AUTOSAR XML (schema 00050)
package /FCADT/ComponentTypes
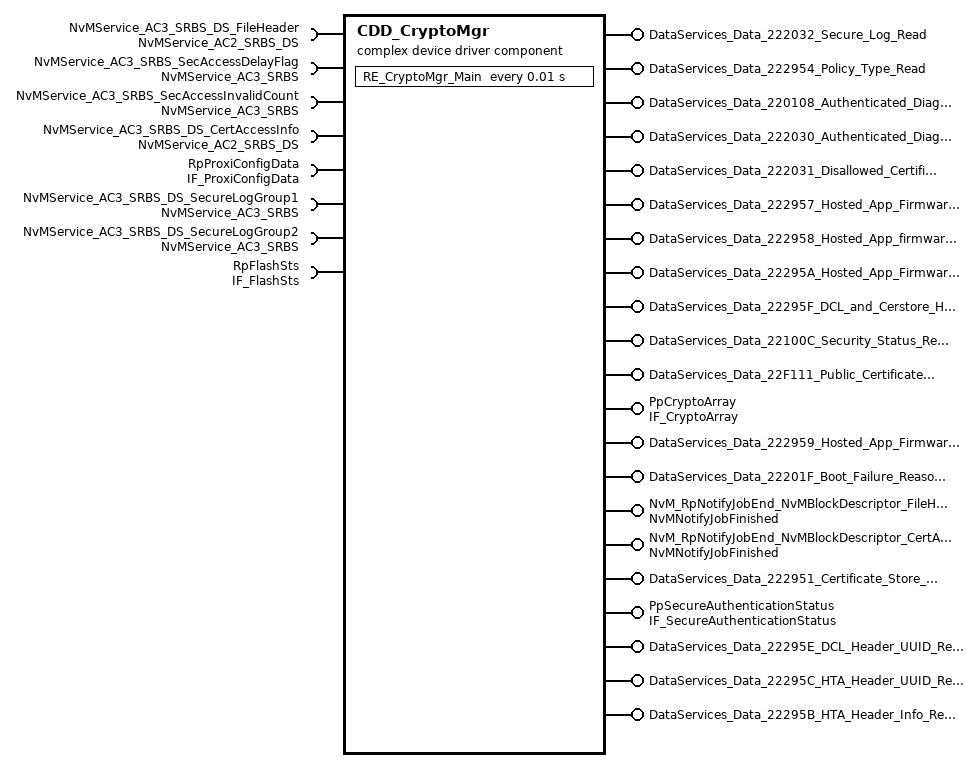
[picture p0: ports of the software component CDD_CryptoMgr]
  complex device driver sw component type CDD_CryptoMgr
    15 x provide port:
      DataServices_Data_222032_Secure_Log_Read: server-com-spec{operation=ReadData, queue-length=1}, provided-interface=DataServices_Data_222032_Secure_Log_Read
      DataServices_Data_222954_Policy_Type_Read: server-com-spec{operation=ReadData, queue-length=1}, provided-interface=DataServices_Data_222954_Policy_Type_Read
      DataServices_Data_220108_Authenticated_Diagnostics_Active_Role_Read: server-com-spec{operation=ReadData, queue-length=1}, provided-interface=DataServices_Data_220108_Authenticated_Diagnostics_Active_Role_Read
      DataServices_Data_222030_Authenticated_Diagnostic_Previous_Access_Read: server-com-spec{operation=ReadData, queue-length=1}, provided-interface=DataServices_Data_222030_Authenticated_Diagnostic_Previous_Access_Read
      DataServices_Data_222031_Disallowed_Certificate_List_Read: server-com-spec{operation=ReadData, queue-length=1}, provided-interface=DataServices_Data_222031_Disallowed_Certificate_List_Read
      DataServices_Data_222957_Hosted_App_Firmware_Header_Info_Read: server-com-spec{operation=ReadData, queue-length=1}, provided-interface=DataServices_Data_222957_Hosted_App_Firmware_Header_Info_Read
      DataServices_Data_222958_Hosted_App_firmware_Header_UUID_Read: server-com-spec{operation=ReadData, queue-length=1}, provided-interface=DataServices_Data_222958_Hosted_App_firmware_Header_UUID_Read
      DataServices_Data_22295A_Hosted_App_Firmware_Cal_Config_Data_Header_UUID_Read: server-com-spec{operation=ReadData, queue-length=1}, provided-interface=DataServices_Data_22295A_Hosted_App_Firmware_Cal_Config_Data_Header_UUID_Read
      DataServices_Data_22295F_DCL_and_Cerstore_Header_Info_Read: server-com-spec{operation=ReadData, queue-length=1}, provided-interface=DataServices_Data_22295F_DCL_and_Cerstore_Header_Info_Read
      DataServices_Data_22100C_Security_Status_Read: server-com-spec{operation=ReadData, queue-length=1}, provided-interface=DataServices_Data_22100C_Security_Status_Read
      DataServices_Data_22F111_Public_Certificates_Regional_Support_Read: server-com-spec{operation=ReadData, queue-length=1}, provided-interface=DataServices_Data_22F111_Public_Certificates_Regional_Support_Read
      PpCryptoArray: server-com-spec{operation=CryptoArray, queue-length=1}, provided-interface=IF_CryptoArray
      DataServices_Data_222959_Hosted_App_Firmware_Cal_Config_Data_Header_Info_Read: server-com-spec{operation=ReadData, queue-length=1}, provided-interface=DataServices_Data_222959_Hosted_App_Firmware_Cal_Config_Data_Header_Info_Read
      DataServices_Data_22201F_Boot_Failure_Reason_Read: server-com-spec{operation=ReadData, queue-length=1}, provided-interface=DataServices_Data_22201F_Boot_Failure_Reason_Read
      NvM_RpNotifyJobEnd_NvMBlockDescriptor_FileHeader: server-com-spec{operation=JobFinished, queue-length=1}, provided-interface=NvMNotifyJobFinished
    4 x require port:
      NvMService_AC3_SRBS_DS_FileHeader: required-com-specs=[WriteBlock, SetRamBlockStatus, SetDataIndex, ReadBlock, GetErrorStatus, GetDataIndex], required-interface=NvMService_AC2_SRBS_DS
      NvMService_AC3_SRBS_SecAccessDelayFlag: required-com-specs=[WriteBlock, SetRamBlockStatus, ReadBlock, InvalidateNvBlock, GetErrorStatus, EraseBlock], required-interface=NvMService_AC3_SRBS
      NvMService_AC3_SRBS_SecAccessInvalidCount: required-com-specs=[WriteBlock, SetRamBlockStatus, ReadBlock, InvalidateNvBlock, GetErrorStatus, EraseBlock], required-interface=NvMService_AC3_SRBS
      NvMService_AC3_SRBS_DS_CertAccessInfo: required-com-specs=[WriteBlock, SetRamBlockStatus, SetDataIndex, ReadBlock, GetErrorStatus, GetDataIndex], required-interface=NvMService_AC2_SRBS_DS
    provide port NvM_RpNotifyJobEnd_NvMBlockDescriptor_CertAccessInfo: server-com-spec{operation=JobFinished, queue-length=1}, provided-interface=NvMNotifyJobFinished
    require port RpProxiConfigData: nonqueued-receiver-com-spec{data-element=ProxiData, filter=data-filter-type=ALWAYS}, required-interface=IF_ProxiConfigData
    provide port DataServices_Data_222951_Certificate_Store_UUID_Read: server-com-spec{operation=ReadData, queue-length=1}, provided-interface=DataServices_Data_222951_Certificate_Store_UUID_Read
    provide port PpSecureAuthenticationStatus: server-com-spec{operation=Get_ADAStatus, queue-length=1}, provided-interface=IF_SecureAuthenticationStatus
    require port NvMService_AC3_SRBS_DS_SecureLogGroup1: required-com-specs=[WriteBlock, SetRamBlockStatus, ReadBlock, InvalidateNvBlock, GetErrorStatus, EraseBlock], required-interface=NvMService_AC3_SRBS
    require port NvMService_AC3_SRBS_DS_SecureLogGroup2: required-com-specs=[WriteBlock, SetRamBlockStatus, ReadBlock, InvalidateNvBlock, GetErrorStatus, EraseBlock], required-interface=NvMService_AC3_SRBS
    provide port DataServices_Data_22295E_DCL_Header_UUID_Read: server-com-spec{operation=ReadData, queue-length=1}, provided-interface=DataServices_Data_22295E_DCL_Header_UUID_Read
    provide port DataServices_Data_22295C_HTA_Header_UUID_Read: server-com-spec{operation=ReadData, queue-length=1}, provided-interface=DataServices_Data_22295C_HTA_Header_UUID_Read
    provide port DataServices_Data_22295B_HTA_Header_Info_Read: server-com-spec{operation=ReadData, queue-length=1}, provided-interface=DataServices_Data_22295B_HTA_Header_Info_Read
    require port RpFlashSts: nonqueued-receiver-com-spec{data-element=v_FlashSts_u16, filter=data-filter-type=ALWAYS, init-value=0}, required-interface=IF_FlashSts
    behavior CDD_CryptoMgr_InternalBehavior
      ar-typed-per-instance-memorys:
        7 x data, all with sw-calibration-access=READ-ONLY:
          Rte_CDD_CryptoMgr_Rte_SWC_CDD_CryptoMngr_SecAccessDelayFlag_MirrorBlock: type=uint8, init-value=0
          Rte_CDD_CryptoMgr_Rte_SWC_CDD_CryptoMngr_SecAccessInvalidCount_MirrorBlock: type=uint8, init-value=0
          Rte_SWC_CDD_CryptoMngr_SecureLogGroup1_MirrorBlock: type=SecureLogRecord_t
          Rte_SWC_CDD_CryptoMngr_SecureLogGroup2_MirrorBlock: type=SecureLogRecord_t
          NvMBlockDescriptor_SecondCounter_MirrorBlock: type=uint32, init-value=0
          NvMBlockDescriptor_SystemTimestamp_MirrorBlock: type=Array_15Bytes, init-value=15 x 0
          NvMBlockDescriptor_CertificateExpired_MirrorBlock: type=boolean, init-value=0
      init event CDD_CryptoMgr_InitEvent: start-on-event=RE_CryptoMgr_Init
      timing event TMT_RE_CryptoMgr_Main: start-on-event=RE_CryptoMgr_Main, period=0.01
      21 x operation invoked event:
        OIT_DataServices_Data_222032_Secure_Log_Read_ReadData_DataServices_Data_222032_Secure_Log_Read_ReadData: start-on-event=DataServices_Data_222032_Secure_Log_Read_ReadData, operation=DataServices_Data_222032_Secure_Log_Read.ReadData
        OIT_DataServices_Data_22295A_Hosted_App_Firmware_Cal_Config_Data_Header_UUID_Read_ReadData_DataServices_Data_22295A_Host0363ECC3: start-on-event=DataServices_Data_22295A_Hosted_App_Firmware_Cal_Config_Data_Header_UUID_Read_ReadData, operation=DataServices_Data_22295A_Hosted_App_Firmware_Cal_Config_Data_Header_UUID_Read.ReadData
        OIT_DataServices_Data_222031_Disallowed_Certificate_List_Read_ReadData_DataServices_Data_222031_Disallowed_Certificate_LC9ECC53E: start-on-event=DataServices_Data_222031_Disallowed_Certificate_List_Read_ReadData, operation=DataServices_Data_222031_Disallowed_Certificate_List_Read.ReadData
        OIT_DataServices_Data_222957_Hosted_App_Firmware_Header_Info_Read_ReadData_DataServices_Data_222957_Hosted_App_Firmware_59835101: start-on-event=DataServices_Data_222957_Hosted_App_Firmware_Header_Info_Read_ReadData, operation=DataServices_Data_222957_Hosted_App_Firmware_Header_Info_Read.ReadData
        OIT_DataServices_Data_220108_Authenticated_Diagnostics_Active_Role_Read_ReadData_DataServices_Data_220108_Authenticated_1848ABFC: start-on-event=DataServices_Data_220108_Authenticated_Diagnostics_Active_Role_Read_ReadData, operation=DataServices_Data_220108_Authenticated_Diagnostics_Active_Role_Read.ReadData
        OIT_DataServices_Data_22295F_DCL_and_Cerstore_Header_Info_Read_ReadData_DataServices_Data_22295F_DCL_and_Cerstore_Header5E694DD0: start-on-event=DataServices_Data_22295F_DCL_and_Cerstore_Header_Info_Read_ReadData, operation=DataServices_Data_22295F_DCL_and_Cerstore_Header_Info_Read.ReadData
        OIT_DataServices_Data_22F111_Public_Certificates_Regional_Support_Read_ReadData_DataServices_Data_22F111_Public_Certific9DA6A63E: start-on-event=DataServices_Data_22F111_Public_Certificates_Regional_Support_Read_ReadData, operation=DataServices_Data_22F111_Public_Certificates_Regional_Support_Read.ReadData
        OIT_DataServices_Data_22100C_Security_Status_Read_ReadData_DataServices_Data_22100C_Security_Status_Read_ReadData: start-on-event=DataServices_Data_22100C_Security_Status_Read_ReadData, operation=DataServices_Data_22100C_Security_Status_Read.ReadData
        OIT_DataServices_Data_222958_Hosted_App_firmware_Header_UUID_Read_ReadData_DataServices_Data_222958_Hosted_App_firmware_60C8C4CE: start-on-event=DataServices_Data_222958_Hosted_App_firmware_Header_UUID_Read_ReadData, operation=DataServices_Data_222958_Hosted_App_firmware_Header_UUID_Read.ReadData
        OIT_DataServices_Data_222954_Policy_Type_Read_ReadData_DataServices_Data_222954_Policy_Type_Read_ReadData: start-on-event=DataServices_Data_222954_Policy_Type_Read_ReadData, operation=DataServices_Data_222954_Policy_Type_Read.ReadData
        OIT_DataServices_Data_222030_Authenticated_Diagnostic_Previous_Access_Read_ReadData_DataServices_Data_222030_Authenticat5BBDD058: start-on-event=DataServices_Data_222030_Authenticated_Diagnostic_Previous_Access_Read_ReadData, operation=DataServices_Data_222030_Authenticated_Diagnostic_Previous_Access_Read.ReadData
        OIT_PpCryptoArray_CryptoArray_PpCryptoArray_CryptoArray: start-on-event=RE_CryptoArray_CryptoArray, operation=PpCryptoArray.CryptoArray
        OIT_DataServices_Data_22201F_Boot_Failure_Reason_Read_ReadData_DataServices_Data_22201F_Boot_Failure_Reason_Read_ReadData: start-on-event=DataServices_Data_22201F_Boot_Failure_Reason_Read_ReadData, operation=DataServices_Data_22201F_Boot_Failure_Reason_Read.ReadData
        OIT_DataServices_Data_222959_Hosted_App_Firmware_Cal_Config_Data_Header_Info_Read_ReadData_DataServices_Data_222959_Host82557262: start-on-event=DataServices_Data_222959_Hosted_App_Firmware_Cal_Config_Data_Header_Info_Read_ReadData, operation=DataServices_Data_222959_Hosted_App_Firmware_Cal_Config_Data_Header_Info_Read.ReadData
        OIT_RE_NvM_RpNotifyJobEnd_NvMBlockDescriptor_FileHeader_JobFinished_NvM_RpNotifyJobEnd_NvMBlockDescriptor_FileHeader_JobFinished: start-on-event=RE_NvM_RpNotifyJobEnd_NvMBlockDescriptor_FileHeader_JobFinished, operation=NvM_RpNotifyJobEnd_NvMBlockDescriptor_FileHeader.JobFinished
        OIT_NvM_RpNotifyJobEnd_NvMBlockDescriptor_CertAccessInfo_JobFinished_NvM_RpNotifyJobEnd_NvMBlockDescriptor_CertAccessInf1353BA01: start-on-event=RE_NvM_RpNotifyJobEnd_NvMBlockDescriptor_CertAccessInfo_JobFinished, operation=NvM_RpNotifyJobEnd_NvMBlockDescriptor_CertAccessInfo.JobFinished
        OIT_DataServices_Data_222951_Certificate_Store_UUID_Read_ReadData_DataServices_Data_222951_Certificate_Store_UUID_Read_ReadData: start-on-event=DataServices_Data_222951_Certificate_Store_UUID_Read_ReadData, operation=DataServices_Data_222951_Certificate_Store_UUID_Read.ReadData
        OIT_PpSecureAuthenticationStatus_Get_SecureAuthenticationStatus_PpSecureAuthenticationStatus_Get_SecureAuthenticationStatus: start-on-event=RE_Get_SecureAuthenticationStatus, operation=PpSecureAuthenticationStatus.Get_ADAStatus
        OIT_Runnable_DataServices_Data_22295E_DCL_Header_UUID_Read_ReadData: start-on-event=DataServices_Data_22295E_DCL_Header_UUID_Read, operation=DataServices_Data_22295E_DCL_Header_UUID_Read.ReadData
        OIT_DataServices_Data_22295B_HTA_Header_Info_Read_DataServices_Data_22295B_HTA_Header_Info_Read_ReadData: start-on-event=DataServices_Data_22295B_HTA_Header_Info_Read, operation=DataServices_Data_22295B_HTA_Header_Info_Read.ReadData
        OIT_Runnable_DataServices_Data_22295C_HTA_Header_UUID_Read_ReadData: start-on-event=DataServices_Data_22295C_HTA_Header_UUID_Read, operation=DataServices_Data_22295C_HTA_Header_UUID_Read.ReadData
      per-instance-parameters:
        7 x parameter data prototype:
          Rte_CDD_CryptoMgr_Rte_SWC_CDD_CryptoMngr_SecAccessDelayFlag_DefaultValue: sw-calibration-access=READ-WRITE, type=uint8, init-value=0
          Rte_CDD_CryptoMgr_Rte_SWC_CDD_CryptoMngr_SecAccessInvalidCount_DefaultValue: sw-calibration-access=READ-WRITE, type=uint8, init-value=0
          Rte_SWC_CDD_CryptoMngr_SecureLogGroup1_DefaultValue: sw-calibration-access=READ-WRITE, type=SecureLogRecord_t
          Rte_SWC_CDD_CryptoMngr_SecureLogGroup2_DefaultValue: sw-calibration-access=READ-WRITE, type=SecureLogRecord_t
          NvMBlockDescriptor_SecondCounter_DefaultValue: sw-calibration-access=READ-ONLY, type=uint32, init-value=0
          NvMBlockDescriptor_SystemTimestamp_DefaultValue: sw-calibration-access=READ-WRITE, type=Array_15Bytes, init-value=15 x 0
          NvMBlockDescriptor_CertificateExpired_DefaultValue: sw-calibration-access=READ-WRITE, type=boolean, init-value=0
      23 x runnable:
        RE_CryptoMgr_Init
          4 x sync call:
            SC_NvMService_AC3_SRBS_DS_FileHeader_ReadBlock: operation=NvMService_AC3_SRBS_DS_FileHeader.ReadBlock
            SC_NvMService_AC3_SRBS_DS_FileHeader_SetDataIndex: operation=NvMService_AC3_SRBS_DS_FileHeader.SetDataIndex
            SC_NvMService_AC3_SRBS_DS_CertAccessInfo_ReadBlock: operation=NvMService_AC3_SRBS_DS_CertAccessInfo.ReadBlock
            SC_NvMService_AC3_SRBS_DS_CertAccessInfo_SetDataIndex: operation=NvMService_AC3_SRBS_DS_CertAccessInfo.SetDataIndex
        RE_CryptoMgr_Main
          data-receive-point-by-arguments:
            access REC_RpFlashSts_v_FlashSts_u16: accessed-variable=RpFlashSts.v_FlashSts_u16
            access REC_RpProxiConfigData_ProxiData: accessed-variable=RpProxiConfigData.ProxiData
          11 x sync call:
            SC_NvMService_AC3_SRBS_SecAccessDelayFlag_GetErrorStatus: operation=NvMService_AC3_SRBS_SecAccessDelayFlag.GetErrorStatus
            SC_NvMService_AC3_SRBS_SecAccessDelayFlag_WriteBlock: operation=NvMService_AC3_SRBS_SecAccessDelayFlag.WriteBlock
            SC_NvMService_AC3_SRBS_SecAccessInvalidCount_GetErrorStatus: operation=NvMService_AC3_SRBS_SecAccessInvalidCount.GetErrorStatus
            SC_NvMService_AC3_SRBS_SecAccessInvalidCount_WriteBlock: operation=NvMService_AC3_SRBS_SecAccessInvalidCount.WriteBlock
            SC_NvMService_AC3_SRBS_DS_CertAccessInfo_WriteBlock: operation=NvMService_AC3_SRBS_DS_CertAccessInfo.WriteBlock
            SC_NvMService_AC3_SRBS_DS_SecureLogGroup1_SetRamBlockStatus: operation=NvMService_AC3_SRBS_DS_SecureLogGroup1.SetRamBlockStatus
            SC_NvMService_AC3_SRBS_DS_SecureLogGroup2_SetRamBlockStatus: operation=NvMService_AC3_SRBS_DS_SecureLogGroup2.SetRamBlockStatus
            SC_NvMService_AC3_SRBS_DS_SecureLogGroup1_GetErrorStatus: operation=NvMService_AC3_SRBS_DS_SecureLogGroup1.GetErrorStatus
            SC_NvMService_AC3_SRBS_DS_SecureLogGroup1_ReadBlock: operation=NvMService_AC3_SRBS_DS_SecureLogGroup1.ReadBlock
            SC_NvMService_AC3_SRBS_DS_SecureLogGroup2_GetErrorStatus: operation=NvMService_AC3_SRBS_DS_SecureLogGroup2.GetErrorStatus
            SC_NvMService_AC3_SRBS_DS_SecureLogGroup2_ReadBlock: operation=NvMService_AC3_SRBS_DS_SecureLogGroup2.ReadBlock
        DataServices_Data_222032_Secure_Log_Read_ReadData
        DataServices_Data_22295A_Hosted_App_Firmware_Cal_Config_Data_Header_UUID_Read_ReadData
        DataServices_Data_222031_Disallowed_Certificate_List_Read_ReadData
        DataServices_Data_222957_Hosted_App_Firmware_Header_Info_Read_ReadData
        DataServices_Data_220108_Authenticated_Diagnostics_Active_Role_Read_ReadData
        DataServices_Data_22295F_DCL_and_Cerstore_Header_Info_Read_ReadData
        DataServices_Data_22F111_Public_Certificates_Regional_Support_Read_ReadData
          data-receive-point-by-arguments:
            access REC_RpProxiConfigData_ProxiData: accessed-variable=RpProxiConfigData.ProxiData
        DataServices_Data_22100C_Security_Status_Read_ReadData
        DataServices_Data_222958_Hosted_App_firmware_Header_UUID_Read_ReadData
        DataServices_Data_222954_Policy_Type_Read_ReadData
        DataServices_Data_222030_Authenticated_Diagnostic_Previous_Access_Read_ReadData
        RE_CryptoArray_CryptoArray
        DataServices_Data_22201F_Boot_Failure_Reason_Read_ReadData
        DataServices_Data_222959_Hosted_App_Firmware_Cal_Config_Data_Header_Info_Read_ReadData
        RE_NvM_RpNotifyJobEnd_NvMBlockDescriptor_FileHeader_JobFinished
        RE_NvM_RpNotifyJobEnd_NvMBlockDescriptor_CertAccessInfo_JobFinished
        DataServices_Data_222951_Certificate_Store_UUID_Read_ReadData
        RE_Get_SecureAuthenticationStatus
        DataServices_Data_22295E_DCL_Header_UUID_Read
        DataServices_Data_22295B_HTA_Header_Info_Read
        DataServices_Data_22295C_HTA_Header_UUID_Read
      7 x swc service dependency, all with category=SERVICE:
        NvMBlockDescriptor_SecAccessDelayFlag
          assigned-datas:
            role=ramBlock, used-data-element=Rte_CDD_CryptoMgr_Rte_SWC_CDD_CryptoMngr_SecAccessDelayFlag_MirrorBlock
            role=defaultValue, used-parameter-element=Rte_CDD_CryptoMgr_Rte_SWC_CDD_CryptoMngr_SecAccessDelayFlag_DefaultValue
          service-needs:
            nv block needs NvMBlockDescriptor_SecAccessDelayFlag: n-data-sets=0, ram-block-status-control=API, reliability=NO-PROTECTION, restore-at-start=true, store-immediate=true
        NvMBlockDescriptor_SecAccessInvalidCount
          assigned-datas:
            role=ramBlock, used-data-element=Rte_CDD_CryptoMgr_Rte_SWC_CDD_CryptoMngr_SecAccessInvalidCount_MirrorBlock
            role=defaultValue, used-parameter-element=Rte_CDD_CryptoMgr_Rte_SWC_CDD_CryptoMngr_SecAccessInvalidCount_DefaultValue
          service-needs:
            nv block needs NvMBlockDescriptor_SecAccessInvalidCount: n-data-sets=0, ram-block-status-control=API, reliability=NO-PROTECTION, restore-at-start=true, store-immediate=true
        NvMBlockDescriptor_SecureLogGroup1: assigned-datas=role-based-data-assignment={role=defaultValue, used-parameter-element=Rte_SWC_CDD_CryptoMngr_SecureLogGroup1_DefaultValue}
          service-needs:
            nv block needs NvMBlockDescriptor_SecureLogGroup1: n-data-sets=0, ram-block-status-control=API, reliability=NO-PROTECTION, store-at-shutdown=true
        NvMBlockDescriptor_SecureLogGroup2: assigned-datas=role-based-data-assignment={role=defaultValue, used-parameter-element=Rte_SWC_CDD_CryptoMngr_SecureLogGroup2_DefaultValue}
          service-needs:
            nv block needs NvMBlockDescriptor_SecureLogGroup2: n-data-sets=0, ram-block-status-control=API, reliability=NO-PROTECTION, store-at-shutdown=true
        NvMBlockDescriptor_SecondCounter
          assigned-datas:
            role=ramBlock, used-data-element=NvMBlockDescriptor_SecondCounter_MirrorBlock
            role=defaultValue, used-parameter-element=NvMBlockDescriptor_SecondCounter_DefaultValue
          service-needs:
            nv block needs NvMBlockDescriptor_SecondCounter: n-data-sets=0, ram-block-status-control=API, reliability=ERROR-DETECTION, resistant-to-changed-sw=true, restore-at-start=true, store-at-shutdown=true, store-immediate=true
        NvMBlockDescriptor_SystemTimestamp
          assigned-datas:
            role=ramBlock, used-data-element=NvMBlockDescriptor_SystemTimestamp_MirrorBlock
            role=defaultValue, used-parameter-element=NvMBlockDescriptor_SystemTimestamp_DefaultValue
          service-needs:
            nv block needs NvMBlockDescriptor_SystemTimestamp: n-data-sets=0, ram-block-status-control=API, reliability=ERROR-DETECTION, restore-at-start=true, store-at-shutdown=true, store-immediate=true
        NvMBlockDescriptor_CertificateExpired
          assigned-datas:
            role=ramBlock, used-data-element=NvMBlockDescriptor_CertificateExpired_MirrorBlock
            role=defaultValue, used-parameter-element=NvMBlockDescriptor_CertificateExpired_DefaultValue
          service-needs:
            nv block needs NvMBlockDescriptor_CertificateExpired: n-data-sets=0, ram-block-status-control=API, reliability=ERROR-DETECTION, resistant-to-changed-sw=true, restore-at-start=true, store-at-shutdown=false, store-immediate=true
  swc implementation CDD_CryptoMgr_Implementation: behavior=CDD_CryptoMgr_InternalBehavior
